AUTOSAR XML (schema 4-0-3)
package /ComponentTypes
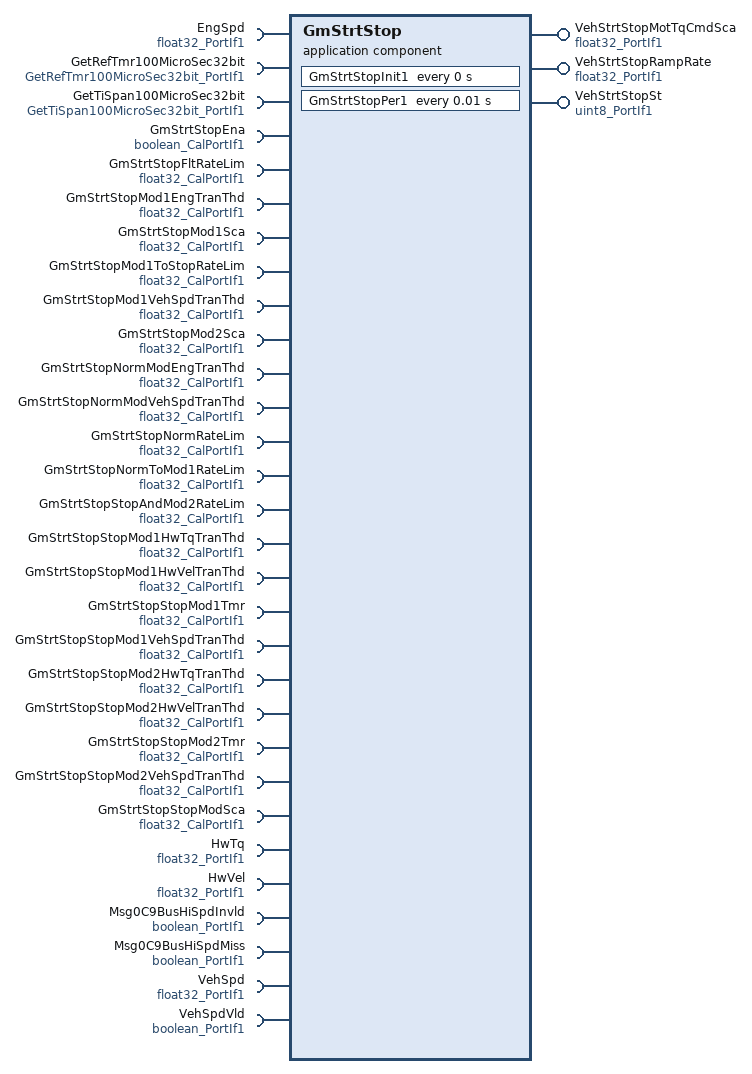
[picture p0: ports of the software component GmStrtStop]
  application sw component type GmStrtStop
    provide port VehStrtStopMotTqCmdSca: nonqueued-sender-com-spec{data-element=Val, init-value=1}, provided-interface=float32_PortIf1
    provide port VehStrtStopRampRate: nonqueued-sender-com-spec{data-element=Val, init-value=0}, provided-interface=float32_PortIf1
    provide port VehStrtStopSt: nonqueued-sender-com-spec{data-element=Val, init-value=0}, provided-interface=uint8_PortIf1
    30 x require port:
      EngSpd: nonqueued-receiver-com-spec{data-element=Val, filter=data-filter-type=ALWAYS, init-value=0}, required-interface=float32_PortIf1
      GetRefTmr100MicroSec32bit: required-interface=GetRefTmr100MicroSec32bit_PortIf1
      GetTiSpan100MicroSec32bit: required-interface=GetTiSpan100MicroSec32bit_PortIf1
      GmStrtStopEna: parameter-require-com-spec{init-value=1, parameter=Logl}, required-interface=boolean_CalPortIf1
      GmStrtStopFltRateLim: parameter-require-com-spec{init-value=2, parameter=Val}, required-interface=float32_CalPortIf1
      GmStrtStopMod1EngTranThd: parameter-require-com-spec{init-value=3000, parameter=Val}, required-interface=float32_CalPortIf1
      GmStrtStopMod1Sca: parameter-require-com-spec{init-value=0.5, parameter=Val}, required-interface=float32_CalPortIf1
      GmStrtStopMod1ToStopRateLim: parameter-require-com-spec{init-value=0.8, parameter=Val}, required-interface=float32_CalPortIf1
      GmStrtStopMod1VehSpdTranThd: parameter-require-com-spec{init-value=10, parameter=Val}, required-interface=float32_CalPortIf1
      GmStrtStopMod2Sca: parameter-require-com-spec{init-value=0.5, parameter=Val}, required-interface=float32_CalPortIf1
      GmStrtStopNormModEngTranThd: parameter-require-com-spec{init-value=3000, parameter=Val}, required-interface=float32_CalPortIf1
      GmStrtStopNormModVehSpdTranThd: parameter-require-com-spec{init-value=12, parameter=Val}, required-interface=float32_CalPortIf1
      GmStrtStopNormRateLim: parameter-require-com-spec{init-value=0.4, parameter=Val}, required-interface=float32_CalPortIf1
      GmStrtStopNormToMod1RateLim: parameter-require-com-spec{init-value=1.5, parameter=Val}, required-interface=float32_CalPortIf1
      GmStrtStopStopAndMod2RateLim: parameter-require-com-spec{init-value=0.5, parameter=Val}, required-interface=float32_CalPortIf1
      GmStrtStopStopMod1HwTqTranThd: parameter-require-com-spec{init-value=1, parameter=Val}, required-interface=float32_CalPortIf1
      GmStrtStopStopMod1HwVelTranThd: parameter-require-com-spec{init-value=10, parameter=Val}, required-interface=float32_CalPortIf1
      GmStrtStopStopMod1Tmr: parameter-require-com-spec{init-value=100, parameter=Val}, required-interface=float32_CalPortIf1
      GmStrtStopStopMod1VehSpdTranThd: parameter-require-com-spec{init-value=5, parameter=Val}, required-interface=float32_CalPortIf1
      GmStrtStopStopMod2HwTqTranThd: parameter-require-com-spec{init-value=1, parameter=Val}, required-interface=float32_CalPortIf1
      GmStrtStopStopMod2HwVelTranThd: parameter-require-com-spec{init-value=10, parameter=Val}, required-interface=float32_CalPortIf1
      GmStrtStopStopMod2Tmr: parameter-require-com-spec{init-value=100, parameter=Val}, required-interface=float32_CalPortIf1
      GmStrtStopStopMod2VehSpdTranThd: parameter-require-com-spec{init-value=8, parameter=Val}, required-interface=float32_CalPortIf1
      GmStrtStopStopModSca: parameter-require-com-spec{init-value=0.001, parameter=Val}, required-interface=float32_CalPortIf1
      HwTq: nonqueued-receiver-com-spec{data-element=Val, filter=data-filter-type=ALWAYS, init-value=0}, required-interface=float32_PortIf1
      HwVel: nonqueued-receiver-com-spec{data-element=Val, filter=data-filter-type=ALWAYS, init-value=0}, required-interface=float32_PortIf1
      Msg0C9BusHiSpdInvld: nonqueued-receiver-com-spec{data-element=Logl, filter=data-filter-type=ALWAYS, init-value=0}, required-interface=boolean_PortIf1
      Msg0C9BusHiSpdMiss: nonqueued-receiver-com-spec{data-element=Logl, filter=data-filter-type=ALWAYS, init-value=0}, required-interface=boolean_PortIf1
      VehSpd: nonqueued-receiver-com-spec{data-element=Val, filter=data-filter-type=ALWAYS, init-value=0}, required-interface=float32_PortIf1
      VehSpdVld: nonqueued-receiver-com-spec{data-element=Logl, filter=data-filter-type=ALWAYS, init-value=0}, required-interface=boolean_PortIf1
    behavior GmStrtStop_InternalBehavior
      ar-typed-per-instance-memorys:
        4 x data, all with sw-calibration-access=READ-ONLY:
          Mod1RefTmr: type=uint32
          Mod2RefTmr: type=uint32
          PrevActSt: type=uint8
          PrevStrtStopSt: type=uint8
      timing event GmStrtStop_InitEvent: start-on-event=GmStrtStopInit1, period=0
      timing event TMT_GmStrtStopPer1: start-on-event=GmStrtStopPer1, period=0.01
      runnable GmStrtStopInit1
        sync call SC_GetRefTmr100MicroSec32bit_Oper: operation=GetRefTmr100MicroSec32bit.Oper, timeout=0
      runnable GmStrtStopPer1
        data-receive-point-by-arguments:
          7 x access:
            REC_EngSpd_Val: accessed-variable=EngSpd.Val
            REC_HwTq_Val: accessed-variable=HwTq.Val
            REC_HwVel_Val: accessed-variable=HwVel.Val
            REC_Msg0C9BusHiSpdInvld_Logl: accessed-variable=Msg0C9BusHiSpdInvld.Logl
            REC_Msg0C9BusHiSpdMiss_Logl: accessed-variable=Msg0C9BusHiSpdMiss.Logl
            REC_VehSpd_Val: accessed-variable=VehSpd.Val
            REC_VehSpdVld_Logl: accessed-variable=VehSpdVld.Logl
        data-send-points:
          access SEND_StrtStopRateLim_Val: accessed-variable=VehStrtStopRampRate.Val
          access SEND_StrtStopSca_Val: accessed-variable=VehStrtStopMotTqCmdSca.Val
          access SEND_StrtStopSt_Val: accessed-variable=VehStrtStopSt.Val
        sync call SC_GetRefTmr100MicroSec32bit_Oper: operation=GetRefTmr100MicroSec32bit.Oper, timeout=0
        sync call SC_GetTiSpan100MicroSec32bit_Oper: operation=GetTiSpan100MicroSec32bit.Oper, timeout=0
  swc implementation GmStrtStop_Implementation: behavior=GmStrtStop_InternalBehavior
    code-descriptors:
      code Default: artifact-descriptors=autosar-engineering-object={short-label=Default, category=SWSRC}
